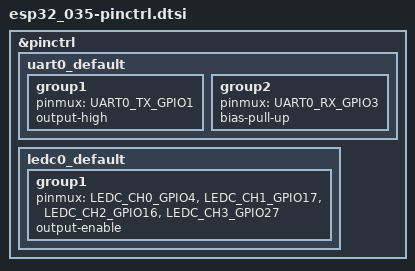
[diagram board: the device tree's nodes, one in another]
/*
 * SPDX-License-Identifier: Apache-2.0
 */

#include <zephyr/dt-bindings/pinctrl/esp32-pinctrl.h>

&pinctrl {
    uart0_default: uart0_default {
        group1 {
            pinmux = <UART0_TX_GPIO1>;
            output-high;
        };

        group2 {
            pinmux = <UART0_RX_GPIO3>;
            bias-pull-up;
        };
    };

    ledc0_default: ledc0_default {
        group1 {
            pinmux = <LEDC_CH0_GPIO4>,
                 <LEDC_CH1_GPIO17>,
                 <LEDC_CH2_GPIO16>,
                 <LEDC_CH3_GPIO27>;
            output-enable;
        };
    };
};
